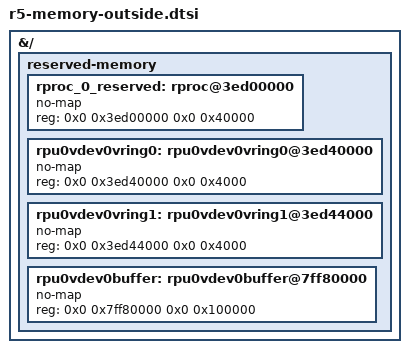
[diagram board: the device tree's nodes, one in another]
/* Reserved memory for the shared memory of one R5F core. The addresses follow the pattern of
   versal-openamp.dtsi in meta-xilinx (core 0). Replace them with the product's memory map. */
&{/} {
	reserved-memory {
		#address-cells = <2>;
		#size-cells = <2>;
		ranges;
		rproc_0_reserved: rproc@3ed00000 {
			no-map;
			reg = <0x0 0x3ed00000 0x0 0x40000>;
		};
		rpu0vdev0vring0: rpu0vdev0vring0@3ed40000 {
			no-map;
			reg = <0x0 0x3ed40000 0x0 0x4000>;
		};
		rpu0vdev0vring1: rpu0vdev0vring1@3ed44000 {
			no-map;
			reg = <0x0 0x3ed44000 0x0 0x4000>;
		};
		rpu0vdev0buffer: rpu0vdev0buffer@7ff80000 {
			no-map;
			reg = <0x0 0x7ff80000 0x0 0x100000>;
		};
	};
};
